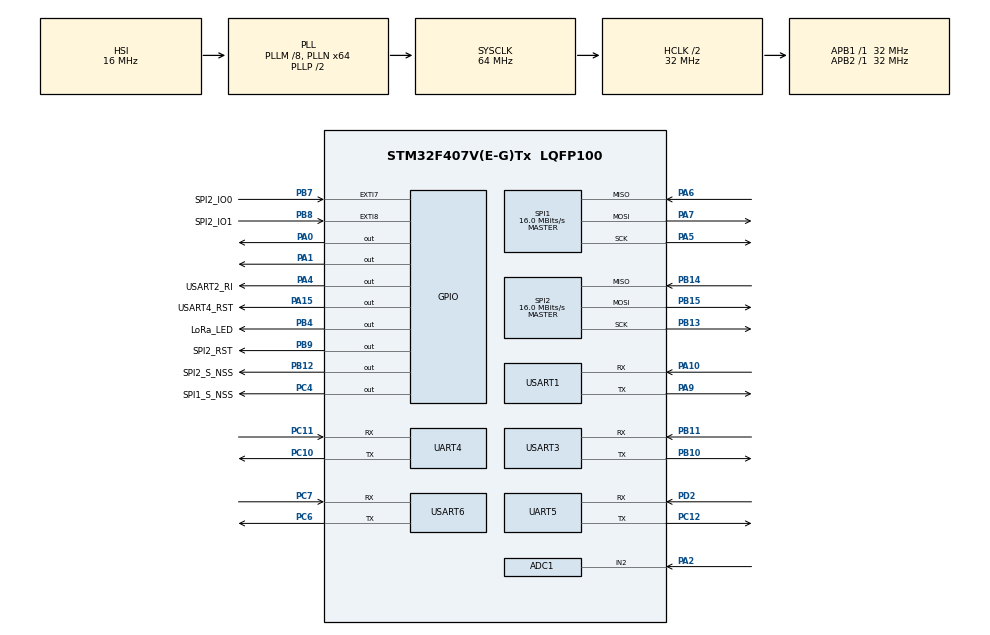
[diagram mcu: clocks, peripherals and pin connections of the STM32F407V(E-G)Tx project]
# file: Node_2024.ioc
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ADC1.Channel-0\#ChannelRegularConversion=ADC_CHANNEL_2
ADC1.NbrOfConversionFlag=1
ADC1.Rank-0\#ChannelRegularConversion=1
ADC1.SamplingTime-0\#ChannelRegularConversion=ADC_SAMPLETIME_3CYCLES
ADC1.master=1
FREERTOS.Tasks01=defaultTask,0,128,StartDefaultTask,Default,NULL,Dynamic,NULL,NULL
IWDG.Prescaler=IWDG_PRESCALER_128
IWDG.Reload=4095
Mcu.Family=STM32F4
Mcu.Name=STM32F407V(E-G)Tx
Mcu.Package=LQFP100
NVIC.PriorityGroup=NVIC_PRIORITYGROUP_4
NVIC.RCC_IRQn=true\:5\:0\:true\:false\:true\:true\:true\:false\:true
NVIC.TIM6_DAC_IRQn=true\:15\:0\:false\:false\:true\:false\:true\:true\:true
NVIC.TimeBase=TIM6_DAC_IRQn
NVIC.TimeBaseIP=TIM6
NVIC.USART3_IRQn=true\:5\:0\:false\:false\:true\:true\:true\:true\:true
NVIC.USART6_IRQn=true\:5\:0\:false\:false\:true\:true\:true\:true\:true
PA0-WKUP.Signal=GPIO_Output
PA1.Signal=GPIO_Output
PA10.Mode=Asynchronous
PA10.Signal=USART1_RX
PA13.Mode=Serial_Wire
PA13.Signal=SYS_JTMS-SWDIO
PA14.Mode=Serial_Wire
PA14.Signal=SYS_JTCK-SWCLK
PA15.GPIO_Label=USART4_RST
PA15.Signal=GPIO_Output
PA2.Signal=ADCx_IN2
PA4.GPIO_Label=USART2_RI
PA4.Signal=GPIO_Output
PA5.Mode=Full_Duplex_Master
PA5.Signal=SPI1_SCK
PA6.Mode=Full_Duplex_Master
PA6.Signal=SPI1_MISO
PA7.Mode=Full_Duplex_Master
PA7.Signal=SPI1_MOSI
PA9.Mode=Asynchronous
PA9.Signal=USART1_TX
PB10.Mode=Asynchronous
PB10.Signal=USART3_TX
PB11.Mode=Asynchronous
PB11.Signal=USART3_RX
PB12.GPIO_Label=SPI2_S_NSS
PB12.Signal=GPIO_Output
PB13.Mode=Full_Duplex_Master
PB13.Signal=SPI2_SCK
PB14.Mode=Full_Duplex_Master
PB14.Signal=SPI2_MISO
PB15.Mode=Full_Duplex_Master
PB15.Signal=SPI2_MOSI
PB4.GPIO_Label=LoRa_LED
PB4.Signal=GPIO_Output
PB7.GPIO_Label=SPI2_IO0
PB7.Signal=GPXTI7
PB8.GPIO_Label=SPI2_IO1
PB8.Signal=GPXTI8
PB9.GPIO_Label=SPI2_RST
PB9.Signal=GPIO_Output
PC10.Mode=Asynchronous
PC10.Signal=UART4_TX
PC11.Mode=Asynchronous
PC11.Signal=UART4_RX
PC12.Mode=Asynchronous
PC12.Signal=UART5_TX
PC14-OSC32_IN.Mode=LSE-External-Oscillator
PC14-OSC32_IN.Signal=RCC_OSC32_IN
PC15-OSC32_OUT.Mode=LSE-External-Oscillator
PC15-OSC32_OUT.Signal=RCC_OSC32_OUT
PC4.GPIO_Label=SPI1_S_NSS
PC4.Signal=GPIO_Output
PC6.Mode=Asynchronous
PC6.Signal=USART6_TX
PC7.Mode=Asynchronous
PC7.Signal=USART6_RX
PD2.Mode=Asynchronous
PD2.Signal=UART5_RX
PH0-OSC_IN.Mode=HSE-External-Oscillator
PH0-OSC_IN.Signal=RCC_OSC_IN
PH1-OSC_OUT.Mode=HSE-External-Oscillator
PH1-OSC_OUT.Signal=RCC_OSC_OUT
ProjectManager.HeapSize=0x200
ProjectManager.StackSize=0x400
ProjectManager.TargetToolchain=MDK-ARM V5.27
RCC.48MHZClocksFreq_Value=42666666.666666664
RCC.AHBCLKDivider=RCC_SYSCLK_DIV2
RCC.AHBFreq_Value=32000000
RCC.APB1Freq_Value=32000000
RCC.APB1TimFreq_Value=32000000
RCC.APB2Freq_Value=32000000
RCC.APB2TimFreq_Value=32000000
RCC.CortexFreq_Value=32000000
RCC.FLatency=FLASH_LATENCY_1
RCC.HCLKFreq_Value=32000000
RCC.HSE_VALUE=16000000
RCC.HSI_VALUE=16000000
RCC.PLLM=8
RCC.PLLN=64
RCC.PLLQ=3
RCC.PREFETCH_ENABLE=0
RCC.SYSCLKFreq_VALUE=64000000
RCC.SYSCLKSource=RCC_SYSCLKSOURCE_PLLCLK
RCC.VCOOutputFreq_Value=128000000
RTC.AlarmDateWeekDay-Alarm\ A=1
RTC.AlarmDateWeekDaySel-Alarm\ A=RTC_ALARMDATEWEEKDAYSEL_DATE
RTC.AlarmSubSecondMask-Alarm\ A=RTC_ALARMSUBSECONDMASK_ALL
RTC.AsynchPrediv=127
RTC.Date=1
RTC.DayLightSaving=RTC_DAYLIGHTSAVING_NONE
RTC.Format=RTC_FORMAT_BCD
RTC.HourFormat=RTC_HOURFORMAT_24
RTC.Hours=0
RTC.Hours_A-Alarm\ A=0
RTC.Minutes=0
RTC.Minutes_A-Alarm\ A=0
RTC.Month=RTC_MONTH_JANUARY
RTC.Seconds=0
RTC.Seconds_A-Alarm\ A=0
RTC.StoreOperation=RTC_STOREOPERATION_RESET
RTC.SubSeconds_A-Alarm\ A=0
RTC.SynchPrediv=255
RTC.WeekDay=RTC_WEEKDAY_MONDAY
RTC.Year=0
SH.ADCx_IN2.0=ADC1_IN2,IN2
SPI1.BaudRatePrescaler=SPI_BAUDRATEPRESCALER_2
SPI1.CLKPhase=SPI_PHASE_1EDGE
SPI1.CLKPolarity=SPI_POLARITY_LOW
SPI1.CRCCalculation=SPI_CRCCALCULATION_DISABLE
SPI1.CalculateBaudRate=16.0 MBits/s
SPI1.DataSize=SPI_DATASIZE_8BIT
SPI1.Direction=SPI_DIRECTION_2LINES
SPI1.FirstBit=SPI_FIRSTBIT_MSB
SPI1.Mode=SPI_MODE_MASTER
SPI1.NSS=SPI_NSS_SOFT
SPI1.TIMode=SPI_TIMODE_DISABLE
SPI1.VirtualType=VM_MASTER
SPI2.BaudRatePrescaler=SPI_BAUDRATEPRESCALER_2
SPI2.CLKPhase=SPI_PHASE_1EDGE
SPI2.CLKPolarity=SPI_POLARITY_LOW
SPI2.CRCCalculation=SPI_CRCCALCULATION_DISABLE
SPI2.CalculateBaudRate=16.0 MBits/s
SPI2.DataSize=SPI_DATASIZE_8BIT
SPI2.Direction=SPI_DIRECTION_2LINES
SPI2.FirstBit=SPI_FIRSTBIT_MSB
SPI2.Mode=SPI_MODE_MASTER
SPI2.NSS=SPI_NSS_SOFT
SPI2.TIMode=SPI_TIMODE_DISABLE
SPI2.VirtualType=VM_MASTER
UART4.VirtualMode=Asynchronous
UART5.VirtualMode=Asynchronous
USART1.VirtualMode=VM_ASYNC
USART3.VirtualMode=VM_ASYNC
USART6.VirtualMode=VM_ASYNC
VP_FREERTOS_VS_CMSIS_V1.Mode=CMSIS_V1
VP_IWDG_VS_IWDG.Mode=IWDG_Activate
VP_RNG_VS_RNG.Mode=RNG_Activate
VP_RTC_VS_RTC_Activate.Mode=RTC_Enabled
VP_RTC_VS_RTC_Calendar.Mode=RTC_Calendar
VP_SYS_VS_tim6.Mode=TIM6
board=custom

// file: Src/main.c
/* USER CODE BEGIN Header */
/**
  ******************************************************************************
  * @file           : main.cpp
  * @brief          : Main program body
  ******************************************************************************
  * @attention
  *
  * Copyright (c) 2024 STMicroelectronics.
  * All rights reserved.
  *
  * This software is licensed under terms that can be found in the LICENSE file
  * in the root directory of this software component.
  * If no LICENSE file comes with this software, it is provided AS-IS.
  *
  ******************************************************************************
  */
/* USER CODE END Header */
#include "main.h"
#include "cmsis_os.h"
#include "adc.h"
#include "iwdg.h"
#include "rng.h"
#include "rtc.h"
#include "spi.h"
#include "usart.h"
#include "gpio.h"

#include <stdio.h>
#include <string.h>
#include "debug_hal.h"

#include "uart1_driver.h"
#include "uart2_driver.h"

#include "main_loadconfig.h"

#include "task_LoRa.h"
#include "task_watchdog.h"
#include "task_InterBoard.h"
#include "sensorAnalog.h"

/* USER CODE BEGIN Includes */

void SystemClock_Config(void);

extern uint8_t Uart5_Rx_data[2];
extern uint8_t Uart1_Rx_data[1024];

uint8_t Uart4_Rx_data[2];
uint16_t time_Check_Lora=0;
/* USER CODE END Includes */

void SystemClock_Config(void);
void MX_FREERTOS_Init(void);

int main(void)
{

  /* MCU Configuration--------------------------------------------------------*/

  /* Reset of all peripherals, Initializes the Flash interface and the Systick. */
  HAL_Init();

  /* Configure the system clock */
  SystemClock_Config();

  /* Initialize all configured peripherals */
  MX_GPIO_Init();
  MX_USART1_UART_Init();
  MX_SPI2_Init();
  MX_RTC_Init();
  MX_SPI1_Init();
  MX_IWDG_Init();
  MX_RNG_Init();
  MX_UART4_Init();
  MX_UART5_Init();
  MX_USART3_UART_Init();
  MX_USART6_UART_Init();
  MX_ADC1_Init();
  /* USER CODE BEGIN 2 */

	Set_Default_System_Config();

		//sem_Modem_Bus = xSemaphoreCreateMutex();
	if(xTaskCreate(task_sysWatchDog, "SysWatchDog", 128, NULL, tskIDLE_PRIORITY + 1, NULL)!= pdPASS)
	{
		DEBUG_D("\r\nERROR: Creat task SYSWATCHDOG false!\r\n");
		fflush(stdout);
	}
  if(xTaskCreate(Task_LoRa, "LoRa",256, NULL, tskIDLE_PRIORITY + 1, NULL)!= pdPASS)
	{
		DEBUG_D("\r\nERROR: Creat task LoRa false!\r\n");
		fflush(stdout);
	}

  /* USER CODE END 2 */

  /* Call init function for freertos objects (in freertos.c) */
  //MX_FREERTOS_Init();

  /* Start scheduler */
  osKernelStart();
  /* We should never get here as control is now taken by the scheduler */
  /* Infinite loop */
  while (1)
  {

  }
}

void SystemClock_Config(void)
{
  RCC_OscInitTypeDef RCC_OscInitStruct = {0};
  RCC_ClkInitTypeDef RCC_ClkInitStruct = {0};

  /** Configure the main internal regulator output voltage
  */
  __HAL_RCC_PWR_CLK_ENABLE();
  __HAL_PWR_VOLTAGESCALING_CONFIG(PWR_REGULATOR_VOLTAGE_SCALE1);

  /** Initializes the RCC Oscillators according to the specified parameters
  * in the RCC_OscInitTypeDef structure.
  */
  RCC_OscInitStruct.OscillatorType = RCC_OSCILLATORTYPE_HSI|RCC_OSCILLATORTYPE_LSI;
  RCC_OscInitStruct.HSIState = RCC_HSI_ON;
  RCC_OscInitStruct.HSICalibrationValue = RCC_HSICALIBRATION_DEFAULT;
  RCC_OscInitStruct.LSIState = RCC_LSI_ON;
  RCC_OscInitStruct.PLL.PLLState = RCC_PLL_ON;
  RCC_OscInitStruct.PLL.PLLSource = RCC_PLLSOURCE_HSI;
  RCC_OscInitStruct.PLL.PLLM = 8;
  RCC_OscInitStruct.PLL.PLLN = 64;
  RCC_OscInitStruct.PLL.PLLP = RCC_PLLP_DIV2;
  RCC_OscInitStruct.PLL.PLLQ = 3;
  if (HAL_RCC_OscConfig(&RCC_OscInitStruct) != HAL_OK)
  {
    Error_Handler();
  }

  /** Initializes the CPU, AHB and APB buses clocks
  */
  RCC_ClkInitStruct.ClockType = RCC_CLOCKTYPE_HCLK|RCC_CLOCKTYPE_SYSCLK
                              |RCC_CLOCKTYPE_PCLK1|RCC_CLOCKTYPE_PCLK2;
  RCC_ClkInitStruct.SYSCLKSource = RCC_SYSCLKSOURCE_PLLCLK;
  RCC_ClkInitStruct.AHBCLKDivider = RCC_SYSCLK_DIV2;
  RCC_ClkInitStruct.APB1CLKDivider = RCC_HCLK_DIV1;
  RCC_ClkInitStruct.APB2CLKDivider = RCC_HCLK_DIV1;

  if (HAL_RCC_ClockConfig(&RCC_ClkInitStruct, FLASH_LATENCY_1) != HAL_OK)
  {
    Error_Handler();
  }
}

void HAL_TIM_PeriodElapsedCallback(TIM_HandleTypeDef *htim)
{
  if (htim->Instance == TIM6) {
    HAL_IncTick();
  }
}

void Error_Handler(void)
{
  __disable_irq();
  while (1)
  {
  }
}

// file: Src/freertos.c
/* USER CODE BEGIN Header */
/**
  ******************************************************************************
  * File Name          : freertos.c
  * Description        : Code for freertos applications
  ******************************************************************************
  * @attention
  *
  * Copyright (c) 2024 STMicroelectronics.
  * All rights reserved.
  *
  * This software is licensed under terms that can be found in the LICENSE file
  * in the root directory of this software component.
  * If no LICENSE file comes with this software, it is provided AS-IS.
  *
  ******************************************************************************
  */
/* USER CODE END Header */

#include "FreeRTOS.h"
#include "task.h"
#include "main.h"
#include "cmsis_os.h"

osThreadId defaultTaskHandle;
osThreadId Task_LoRaHandle;
osThreadId task_sysWatchDoHandle;

void StartDefaultTask(void const * argument);
void StartTask02(void const * argument);
void StartTask03(void const * argument);

void MX_FREERTOS_Init(void); /* (MISRA C 2004 rule 8.1) */

/* GetIdleTaskMemory prototype (linked to static allocation support) */
void vApplicationGetIdleTaskMemory( StaticTask_t **ppxIdleTaskTCBBuffer, StackType_t **ppxIdleTaskStackBuffer, uint32_t *pulIdleTaskStackSize );

/* USER CODE BEGIN GET_IDLE_TASK_MEMORY */
static StaticTask_t xIdleTaskTCBBuffer;
static StackType_t xIdleStack[configMINIMAL_STACK_SIZE];

void vApplicationGetIdleTaskMemory( StaticTask_t **ppxIdleTaskTCBBuffer, StackType_t **ppxIdleTaskStackBuffer, uint32_t *pulIdleTaskStackSize )
{
  *ppxIdleTaskTCBBuffer = &xIdleTaskTCBBuffer;
  *ppxIdleTaskStackBuffer = &xIdleStack[0];
  *pulIdleTaskStackSize = configMINIMAL_STACK_SIZE;
  /* place for user code */
}
/* USER CODE END GET_IDLE_TASK_MEMORY */

void MX_FREERTOS_Init(void) {

  /* Create the thread(s) */
  /* definition and creation of defaultTask */
  osThreadDef(defaultTask, StartDefaultTask, osPriorityNormal, 0, 128);
  defaultTaskHandle = osThreadCreate(osThread(defaultTask), NULL);

  /* definition and creation of Task_LoRa */
  osThreadDef(Task_LoRa, StartTask02, osPriorityNormal, 0, 128);
  Task_LoRaHandle = osThreadCreate(osThread(Task_LoRa), NULL);

  /* definition and creation of task_sysWatchDo */
  osThreadDef(task_sysWatchDo, StartTask03, osPriorityNormal, 0, 128);
  task_sysWatchDoHandle = osThreadCreate(osThread(task_sysWatchDo), NULL);

}

void StartDefaultTask(void const * argument)
{
  for(;;)
  {
    osDelay(1);
  }
}

void StartTask02(void const * argument)
{
  for(;;)
  {
    osDelay(1);
  }
}

void StartTask03(void const * argument)
{
  for(;;)
  {
    osDelay(1);
  }
}
